# STM32F446 register map
File version: 1.7
CPU: CM4 r0p1, little endian, MPU, FPU, 4 interrupt priority bits
Registers are 32-bit, read-write, reset 0x0 unless marked. A register's access mark holds for its fields unless they carry their own. Offsets are from the block's base; [hi:lo] are bit positions; {n}, {i} and the like mark numbered series.

## DCMI — Digital camera interface
Base 0x50050000
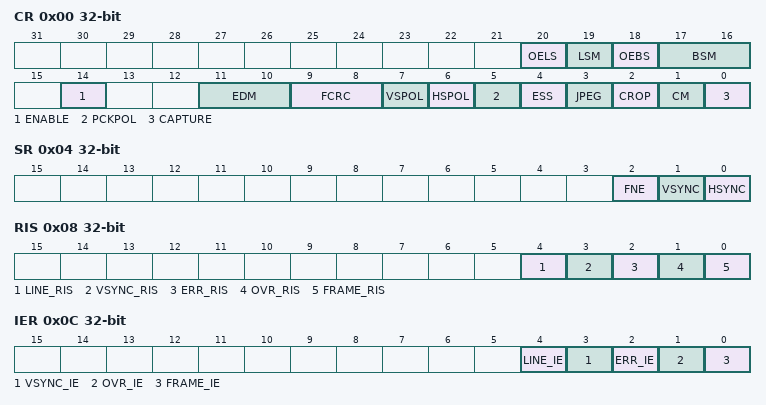
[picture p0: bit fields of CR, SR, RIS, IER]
0x00 CR access per field — control register 1
  [20] OELS ro — Odd/Even Line Select
  [19] LSM ro — Line Select mode
  [18] OEBS ro — Odd/Even Byte Select
  [17:16] BSM ro — Byte Select mode
  [14] ENABLE rw — DCMI enable
  [11:10] EDM rw — Extended data mode
  [9:8] FCRC rw — Frame capture rate control
  [7] VSPOL rw — Vertical synchronization polarity
  [6] HSPOL rw — Horizontal synchronization polarity
  [5] PCKPOL rw — Pixel clock polarity
  [4] ESS rw — Embedded synchronization select
  [3] JPEG rw — JPEG format
  [2] CROP rw — Crop feature
  [1] CM rw — Capture mode
  [0] CAPTURE ro — Capture enable
0x04 SR ro — status register
  [2] FNE — FIFO not empty
  [1] VSYNC
  [0] HSYNC
0x08 RIS ro — raw interrupt status register
  [4] LINE_RIS — Line raw interrupt status
  [3] VSYNC_RIS — VSYNC raw interrupt status
  [2] ERR_RIS — Synchronization error raw interrupt status
  [1] OVR_RIS — Overrun raw interrupt status
  [0] FRAME_RIS — Capture complete raw interrupt status
0x0C IER — interrupt enable register
  [4] LINE_IE — Line interrupt enable
  [3] VSYNC_IE — VSYNC interrupt enable
  [2] ERR_IE — Synchronization error interrupt enable
  [1] OVR_IE — Overrun interrupt enable
  [0] FRAME_IE — Capture complete interrupt enable
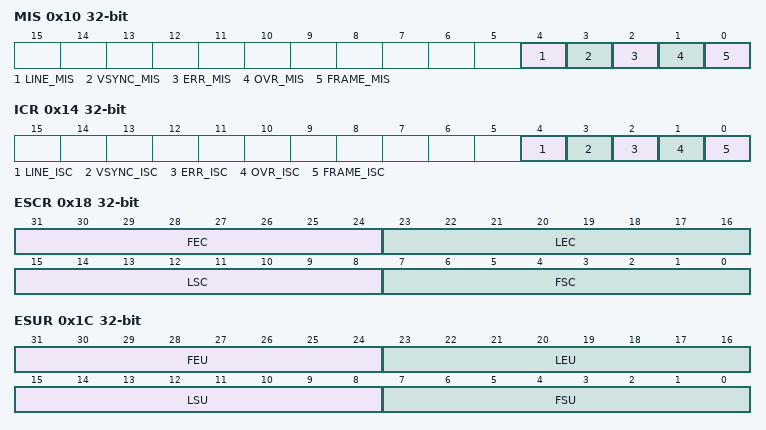
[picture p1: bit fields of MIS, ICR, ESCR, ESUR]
0x10 MIS ro — masked interrupt status register
  [4] LINE_MIS — Line masked interrupt status
  [3] VSYNC_MIS — VSYNC masked interrupt status
  [2] ERR_MIS — Synchronization error masked interrupt status
  [1] OVR_MIS — Overrun masked interrupt status
  [0] FRAME_MIS — Capture complete masked interrupt status
0x14 ICR wo — interrupt clear register
  [4] LINE_ISC — line interrupt status clear
  [3] VSYNC_ISC — Vertical synch interrupt status clear
  [2] ERR_ISC — Synchronization error interrupt status clear
  [1] OVR_ISC — Overrun interrupt status clear
  [0] FRAME_ISC — Capture complete interrupt status clear
0x18 ESCR — embedded synchronization code register
  [31:24] FEC — Frame end delimiter code
  [23:16] LEC — Line end delimiter code
  [15:8] LSC — Line start delimiter code
  [7:0] FSC — Frame start delimiter code
0x1C ESUR — embedded synchronization unmask register
  [31:24] FEU — Frame end delimiter unmask
  [23:16] LEU — Line end delimiter unmask
  [15:8] LSU — Line start delimiter unmask
  [7:0] FSU — Frame start delimiter unmask
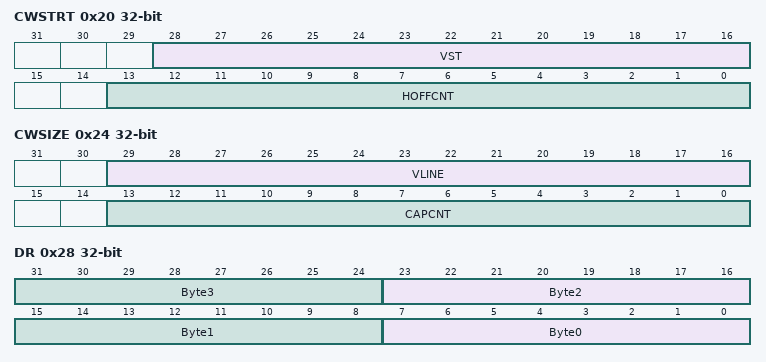
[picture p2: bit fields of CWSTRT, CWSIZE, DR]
0x20 CWSTRT — crop window start
  [28:16] VST — Vertical start line count
  [13:0] HOFFCNT — Horizontal offset count
0x24 CWSIZE — crop window size
  [29:16] VLINE — Vertical line count
  [13:0] CAPCNT — Capture count
0x28 DR ro — data register
  [8n+7:8n] Byte{n} (n=0..3) — Data byte {n}
0x42 CR2 access not given

## DBG — Debug support
Base 0xE0042000
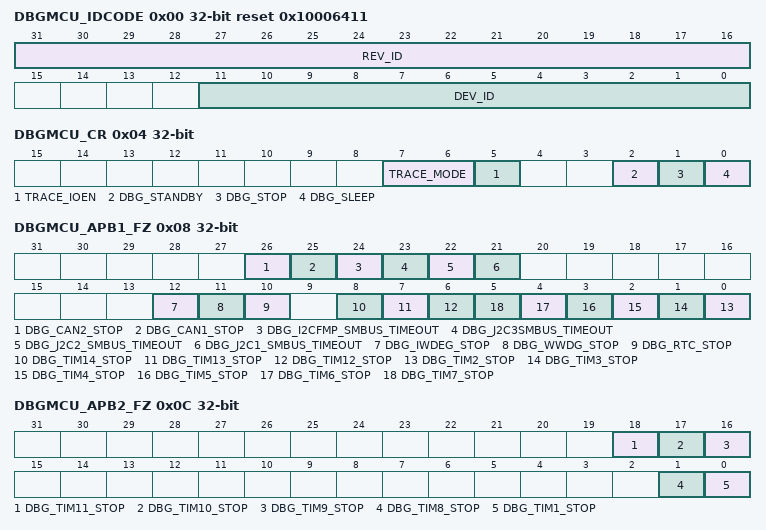
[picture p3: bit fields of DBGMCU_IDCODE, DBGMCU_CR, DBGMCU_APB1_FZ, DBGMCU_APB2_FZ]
0x00 DBGMCU_IDCODE ro reset 0x10006411 — IDCODE
  [31:16] REV_ID, [11:0] DEV_ID
0x04 DBGMCU_CR — Control Register
  [7:6] TRACE_MODE, [5] TRACE_IOEN, [2] DBG_STANDBY, [1] DBG_STOP, [0] DBG_SLEEP
0x08 DBGMCU_APB1_FZ — Debug MCU APB1 Freeze registe
  [26] DBG_CAN2_STOP
  [25] DBG_CAN1_STOP
  [24] DBG_I2CFMP_SMBUS_TIMEOUT — SMBUS timeout mode stopped when Core is halted
  [23] DBG_J2C3SMBUS_TIMEOUT
  [22] DBG_J2C2_SMBUS_TIMEOUT
  [21] DBG_J2C1_SMBUS_TIMEOUT
  [12] DBG_IWDEG_STOP
  [11] DBG_WWDG_STOP
  [10] DBG_RTC_STOP — RTC stopped when Core is halted
  [8] DBG_TIM14_STOP
  [7] DBG_TIM13_STOP
  [6] DBG_TIM12_STOP
  [n-2] DBG_TIM{n}_STOP (n=2..7)
0x0C DBGMCU_APB2_FZ — Debug MCU APB2 Freeze registe
  [18] DBG_TIM11_STOP — TIM11 counter stopped when core is halted
  [17] DBG_TIM10_STOP — TIM10 counter stopped when core is halted
  [16] DBG_TIM9_STOP — TIM9 counter stopped when core is halted
  [1] DBG_TIM8_STOP — TIM8 counter stopped when core is halted
  [0] DBG_TIM1_STOP — TIM1 counter stopped when core is halted

## Notices in the file
Copyright (c) 2022 STMicroelectronics.
SPDX-License-Identifier: Apache-2.0
Licensed under the Apache License, Version 2.0 (the "License");
you may not use this file except in compliance with the License.
You may obtain a copy of the License at
http://www.apache.org/licenses/LICENSE-2.0
Unless required by applicable law or agreed to in writing, software
distributed under the License is distributed on an "AS IS" BASIS,
WITHOUT WARRANTIES OR CONDITIONS OF ANY KIND, either express or implied.
See the License for the specific language governing permissions and
limitations under the License.
